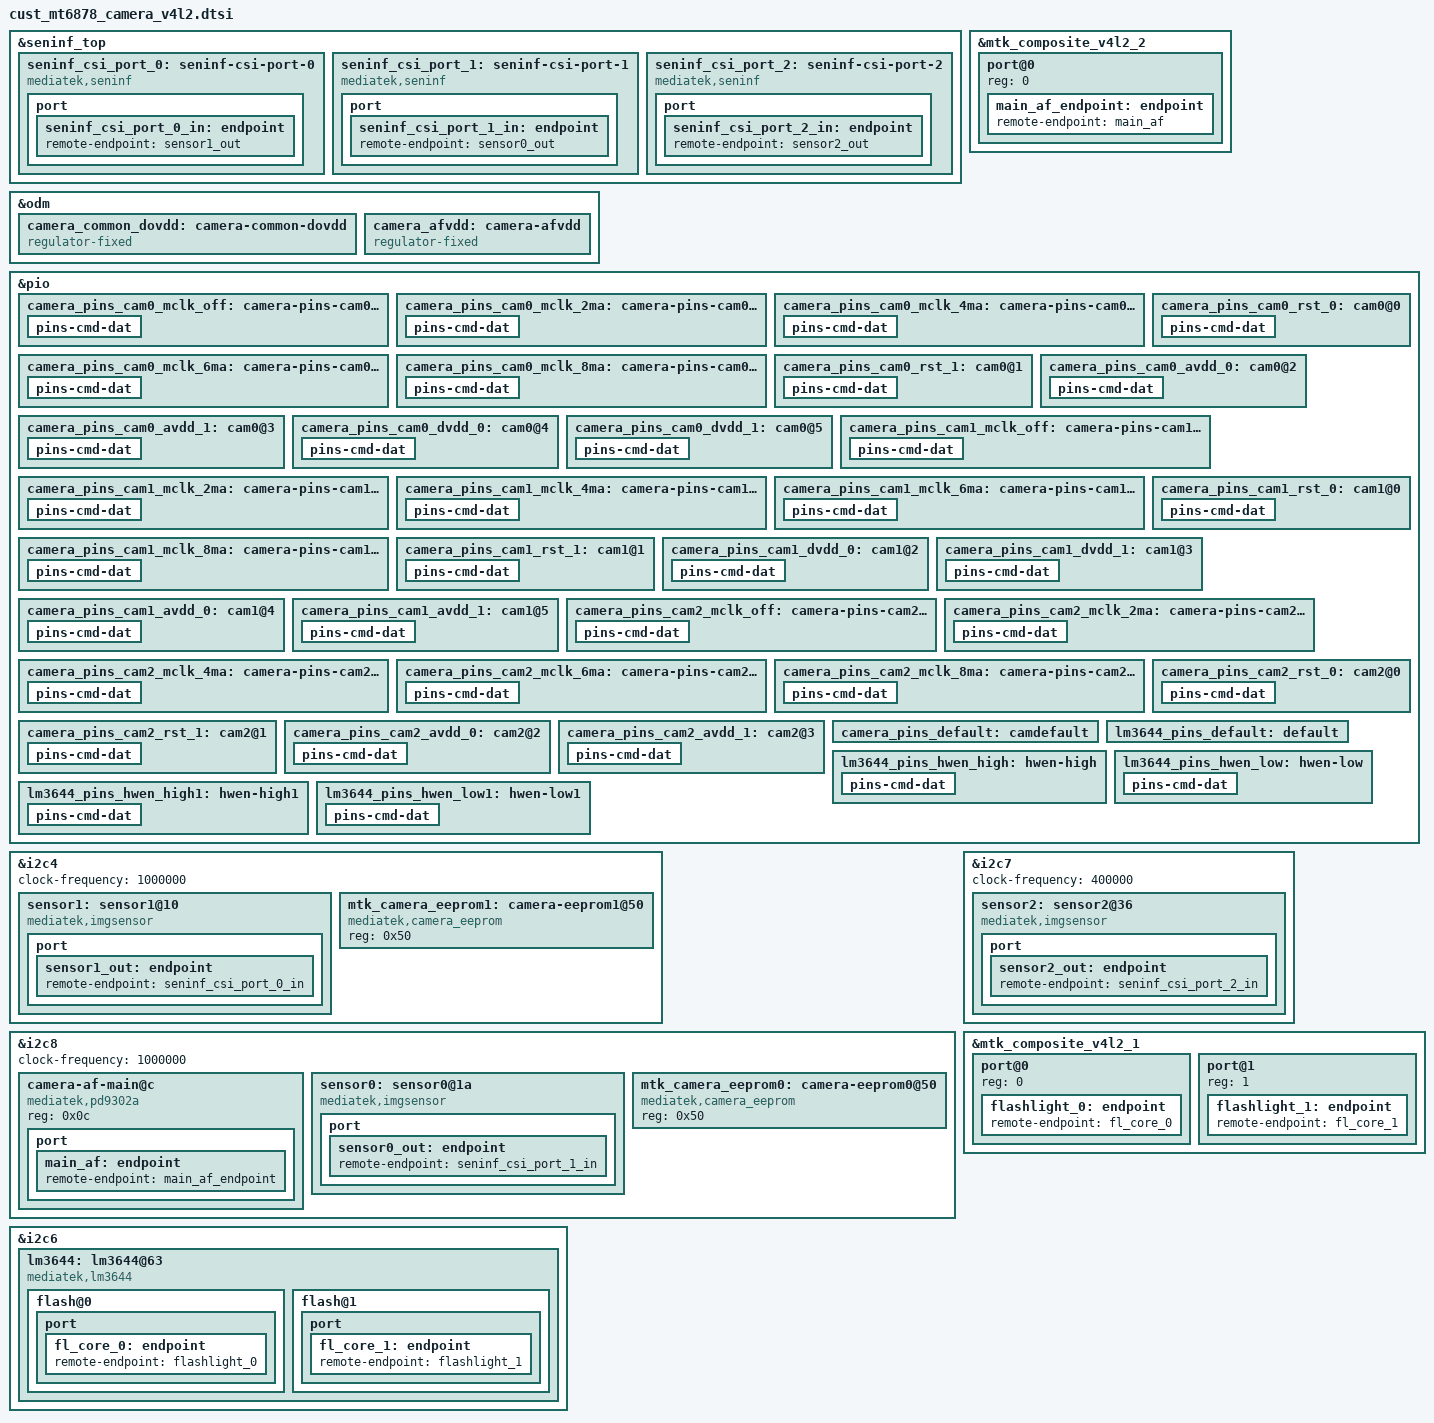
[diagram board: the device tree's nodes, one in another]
// SPDX-License-Identifier: GPL-2.0
/* Copyright (c) 2020 MediaTek Inc. */
#include <dt-bindings/clock/mt6878-clk.h>

&seninf_top {
		seninf_csi_port_0: seninf-csi-port-0 {
			compatible = "mediatek,seninf";
			csi-port = "0";
			dphy-settle-delay-dt = <17>;
			nvmem-cells = <&csi_efuse0>;
			nvmem-cell-names = "rg_csi";
			port {
				seninf_csi_port_0_in: endpoint {
					remote-endpoint = <&sensor1_out>;
				};
			};
		};

		seninf_csi_port_1: seninf-csi-port-1 {
			compatible = "mediatek,seninf";
			csi-port = "1";
			hs-trail-parameter = <0x20>;
			nvmem-cells = <&csi_efuse1>;
			nvmem-cell-names = "rg_csi";
			port {
				seninf_csi_port_1_in: endpoint {
					remote-endpoint = <&sensor0_out>;
				};
			};
		};

		seninf_csi_port_2: seninf-csi-port-2 {
			compatible = "mediatek,seninf";
			csi-port = "2A";
			hs-trail-parameter = <0x20>;
			nvmem-cells = <&csi_efuse2>;
			nvmem-cell-names = "rg_csi";
			port {
				seninf_csi_port_2_in: endpoint {
					remote-endpoint = <&sensor2_out>;
				};
			};
		};
};


/* CAMERA GPIO fixed to regulator */
&odm {
	camera_common_dovdd: camera-common-dovdd {
		compatible = "regulator-fixed";
		regulator-name = "camera-common-dovdd";
		regulator-min-microvolt = <1800000>;
		regulator-max-microvolt = <1800000>;
		enable-active-high;
		gpio = <&pio 23 0x0>;
	};
	camera_afvdd: camera-afvdd {
		compatible = "regulator-fixed";
		regulator-name = "camera-afvdd";
		regulator-min-microvolt = <2800000>;
		regulator-max-microvolt = <2800000>;
		enable-active-high;
		gpio = <&pio 1 0x0>;
	};
};

&mtk_composite_v4l2_2 {
	#address-cells = <1>;
	#size-cells = <0>;
	port@0 {
		reg = <0>;
		main_af_endpoint: endpoint {
			remote-endpoint = <&main_af>;
		};
	};
};

/* CAMERA GPIO standardization */
&pio {
	camera_pins_cam0_mclk_off: camera-pins-cam0-mclk-off {
		pins-cmd-dat {
			pinmux = <PINMUX_GPIO93__FUNC_GPIO93>;
			drive-strength = <1>;
		};
	};
	camera_pins_cam0_mclk_2ma: camera-pins-cam0-mclk-2ma {
		pins-cmd-dat {
			pinmux = <PINMUX_GPIO93__FUNC_CMMCLK1>;
			drive-strength = <0>;
		};
	};
	camera_pins_cam0_mclk_4ma: camera-pins-cam0-mclk-4ma {
		pins-cmd-dat {
			pinmux = <PINMUX_GPIO93__FUNC_CMMCLK1>;
			drive-strength = <1>;
		};
	};
	camera_pins_cam0_mclk_6ma: camera-pins-cam0-mclk-6ma {
		pins-cmd-dat {
			pinmux = <PINMUX_GPIO93__FUNC_CMMCLK1>;
			drive-strength = <2>;
		};
	};
	camera_pins_cam0_mclk_8ma: camera-pins-cam0-mclk-8ma {
		pins-cmd-dat {
			pinmux = <PINMUX_GPIO93__FUNC_CMMCLK1>;
			drive-strength = <3>;
		};
	};
	camera_pins_cam0_rst_0: cam0@0 {
		pins-cmd-dat {
			pinmux = <PINMUX_GPIO25__FUNC_GPIO25>;
			slew-rate = <1>;
			output-low;
		};
	};
	camera_pins_cam0_rst_1: cam0@1 {
		pins-cmd-dat {
			pinmux = <PINMUX_GPIO25__FUNC_GPIO25>;
			slew-rate = <1>;
			output-high;
		};
	};
	camera_pins_cam0_avdd_0: cam0@2 {
		pins-cmd-dat {
			pinmux = <PINMUX_GPIO22__FUNC_GPIO22>;
			slew-rate = <1>;
			output-low;
		};
	};
	camera_pins_cam0_avdd_1: cam0@3 {
		pins-cmd-dat {
			pinmux = <PINMUX_GPIO22__FUNC_GPIO22>;
			slew-rate = <1>;
			output-high;
		};
	};
	camera_pins_cam0_dvdd_0: cam0@4 {
		pins-cmd-dat {
			pinmux = <PINMUX_GPIO21__FUNC_GPIO21>;
			slew-rate = <1>;
			output-low;
		};
	};
	camera_pins_cam0_dvdd_1: cam0@5 {
		pins-cmd-dat {
			pinmux = <PINMUX_GPIO21__FUNC_GPIO21>;
			slew-rate = <1>;
			output-high;
		};
	};

	camera_pins_cam1_mclk_off: camera-pins-cam1-mclk-off {
		pins-cmd-dat {
			pinmux = <PINMUX_GPIO96__FUNC_GPIO96>;
			drive-strength = <1>;
		};
	};
	camera_pins_cam1_mclk_2ma: camera-pins-cam1-mclk-2ma {
		pins-cmd-dat {
			pinmux = <PINMUX_GPIO96__FUNC_CMMCLK4>;
			drive-strength = <0>;
		};
	};
	camera_pins_cam1_mclk_4ma: camera-pins-cam1-mclk-4ma {
		pins-cmd-dat {
			pinmux = <PINMUX_GPIO96__FUNC_CMMCLK4>;
			drive-strength = <1>;
		};
	};
	camera_pins_cam1_mclk_6ma: camera-pins-cam1-mclk-6ma {
		pins-cmd-dat {
			pinmux = <PINMUX_GPIO96__FUNC_CMMCLK4>;
			drive-strength = <2>;
		};
	};
	camera_pins_cam1_mclk_8ma: camera-pins-cam1-mclk-8ma {
		pins-cmd-dat {
			pinmux = <PINMUX_GPIO96__FUNC_CMMCLK4>;
			drive-strength = <3>;
		};
	};
	camera_pins_cam1_rst_0: cam1@0 {
		pins-cmd-dat {
			pinmux = <PINMUX_GPIO24__FUNC_GPIO24>;
			slew-rate = <1>;
			output-low;
		};
	};
	camera_pins_cam1_rst_1: cam1@1 {
		pins-cmd-dat {
			pinmux = <PINMUX_GPIO24__FUNC_GPIO24>;
			slew-rate = <1>;
			output-high;
		};
	};
	camera_pins_cam1_dvdd_0: cam1@2 {
		pins-cmd-dat {
			pinmux = <PINMUX_GPIO20__FUNC_GPIO20>;
			slew-rate = <1>;
			output-low;
		};
	};
	camera_pins_cam1_dvdd_1: cam1@3 {
		pins-cmd-dat {
			pinmux = <PINMUX_GPIO20__FUNC_GPIO20>;
			slew-rate = <1>;
			output-high;
		};
	};
	camera_pins_cam1_avdd_0: cam1@4 {
		pins-cmd-dat {
			pinmux = <PINMUX_GPIO19__FUNC_GPIO19>;
			slew-rate = <1>;
			output-low;
		};
	};
	camera_pins_cam1_avdd_1: cam1@5 {
		pins-cmd-dat {
			pinmux = <PINMUX_GPIO19__FUNC_GPIO19>;
			slew-rate = <1>;
			output-high;
		};
	};

	camera_pins_cam2_mclk_off: camera-pins-cam2-mclk-off {
		pins-cmd-dat {
			pinmux = <PINMUX_GPIO94__FUNC_GPIO94>;
			drive-strength = <1>;
		};
	};
	camera_pins_cam2_mclk_2ma: camera-pins-cam2-mclk-2ma {
		pins-cmd-dat {
			pinmux = <PINMUX_GPIO94__FUNC_CMMCLK2>;
			drive-strength = <0>;
		};
	};
	camera_pins_cam2_mclk_4ma: camera-pins-cam2-mclk-4ma {
		pins-cmd-dat {
			pinmux = <PINMUX_GPIO94__FUNC_CMMCLK2>;
			drive-strength = <1>;
		};
	};
	camera_pins_cam2_mclk_6ma: camera-pins-cam2-mclk-6ma {
		pins-cmd-dat {
			pinmux = <PINMUX_GPIO94__FUNC_CMMCLK2>;
			drive-strength = <2>;
		};
	};
	camera_pins_cam2_mclk_8ma: camera-pins-cam2-mclk-8ma {
		pins-cmd-dat {
			pinmux = <PINMUX_GPIO94__FUNC_CMMCLK2>;
			drive-strength = <3>;
		};
	};
	camera_pins_cam2_rst_0: cam2@0 {
		pins-cmd-dat {
			pinmux = <PINMUX_GPIO26__FUNC_GPIO26>;
			slew-rate = <1>;
			output-low;
		};
	};
	camera_pins_cam2_rst_1: cam2@1 {
		pins-cmd-dat {
			pinmux = <PINMUX_GPIO26__FUNC_GPIO26>;
			slew-rate = <1>;
			output-high;
		};
	};
	camera_pins_cam2_avdd_0: cam2@2 {
		pins-cmd-dat {
			pinmux = <PINMUX_GPIO28__FUNC_GPIO28>;
			slew-rate = <1>;
			output-low;
		};
	};
	camera_pins_cam2_avdd_1: cam2@3 {
		pins-cmd-dat {
			pinmux = <PINMUX_GPIO28__FUNC_GPIO28>;
			slew-rate = <1>;
			output-high;
		};
	};
	camera_pins_default: camdefault {
	};
};
/* CAMERA GPIO end */


&i2c4 {
	status = "okay";
	clock-frequency = <1000000>;

	sensor1: sensor1@10 {
		compatible = "mediatek,imgsensor";
		sensor-names = "gc16b3c_mipi_raw","gc16b3ctxd_mipi_raw";
		reg = <0x10>;

		#thermal-sensor-cells = <0>;

		pinctrl-names = "mclk_off",
				"mclk_2mA",
				"mclk_4mA",
				"mclk_6mA",
				"mclk_8mA",
				"rst_low",
				"rst_high",
				"dvdd_off",
				"dvdd_on",
				"avdd_off",
				"avdd_on";
		pinctrl-0 = <&camera_pins_cam1_mclk_off>;
		pinctrl-1 = <&camera_pins_cam1_mclk_2ma>;
		pinctrl-2 = <&camera_pins_cam1_mclk_4ma>;
		pinctrl-3 = <&camera_pins_cam1_mclk_6ma>;
		pinctrl-4 = <&camera_pins_cam1_mclk_8ma>;
		pinctrl-5 = <&camera_pins_cam1_rst_0>;
		pinctrl-6 = <&camera_pins_cam1_rst_1>;
		pinctrl-7 = <&camera_pins_cam1_dvdd_0>;
		pinctrl-8 = <&camera_pins_cam1_dvdd_1>;
		pinctrl-9 = <&camera_pins_cam1_avdd_0>;
		pinctrl-10 = <&camera_pins_cam1_avdd_1>;

		dovdd-supply = <&camera_common_dovdd>;
		clocks = <&topckgen_clk CLK_TOP_UVPLL192M_D32>,
			<&topckgen_clk CLK_TOP_UVPLL192M_D16>,
			<&topckgen_clk CLK_TOP_OSC_D20>,
			<&topckgen_clk CLK_TOP_UVPLL192M_D10>,
			<&topckgen_clk CLK_TOP_UVPLL192M_D8>,
			<&topckgen_clk CLK_TOP_TCK_26M_MX9>,
			<&topckgen_clk CLK_TOP_UNIVPLL_D6_D8>,
			<&topckgen_clk CLK_TOP_CAMTG5_SEL>;
		clock-names = "6", "12", "13", "19.2", "24", "26", "52", "mclk";

		status = "okay";
		port {
			sensor1_out: endpoint {
				remote-endpoint = <&seninf_csi_port_0_in>;
			};
		};
	};
	mtk_camera_eeprom1:camera-eeprom1@50 {
		compatible = "mediatek,camera_eeprom";
		reg = <0x50>;
		status = "okay";
	};
};


&i2c8 {
	status = "okay";
	clock-frequency = <1000000>;

	camera-af-main@c {
		compatible = "mediatek,pd9302a";
		reg = <0x0c>;
		port {
			main_af: endpoint {
				remote-endpoint = <&main_af_endpoint>;
			};
		};
	};

	sensor0: sensor0@1a {
		compatible = "mediatek,imgsensor";
		sensor-names = "imx882_mipi_raw", "imx882txd_mipi_raw";
		reg = <0x1a>;

		#thermal-sensor-cells = <0>;

		pinctrl-names = "mclk_off",
				"mclk_2mA",
				"mclk_4mA",
				"mclk_6mA",
				"mclk_8mA",
				"rst_low",
				"rst_high",
				"avdd_off",
				"avdd_on",
				"dvdd_off",
				"dvdd_on";

		pinctrl-0 = <&camera_pins_cam0_mclk_off>;
		pinctrl-1 = <&camera_pins_cam0_mclk_2ma>;
		pinctrl-2 = <&camera_pins_cam0_mclk_4ma>;
		pinctrl-3 = <&camera_pins_cam0_mclk_6ma>;
		pinctrl-4 = <&camera_pins_cam0_mclk_8ma>;
		pinctrl-5 = <&camera_pins_cam0_rst_0>;
		pinctrl-6 = <&camera_pins_cam0_rst_1>;
		pinctrl-7 = <&camera_pins_cam0_avdd_0>;
		pinctrl-8 = <&camera_pins_cam0_avdd_1>;
		pinctrl-9 = <&camera_pins_cam0_dvdd_0>;
		pinctrl-10 = <&camera_pins_cam0_dvdd_1>;
		afvdd-supply = <&camera_afvdd>;
		dovdd-supply = <&camera_common_dovdd>;
		clocks = <&topckgen_clk CLK_TOP_UVPLL192M_D32>,
			<&topckgen_clk CLK_TOP_UVPLL192M_D16>,
			<&topckgen_clk CLK_TOP_OSC_D20>,
			<&topckgen_clk CLK_TOP_UVPLL192M_D10>,
			<&topckgen_clk CLK_TOP_UVPLL192M_D8>,
			<&topckgen_clk CLK_TOP_TCK_26M_MX9>,
			<&topckgen_clk CLK_TOP_UNIVPLL_D6_D8>,
			<&topckgen_clk CLK_TOP_CAMTG2_SEL>;
		clock-names = "6", "12", "13", "19.2", "24", "26", "52", "mclk";


		status = "okay";
		port {
			sensor0_out: endpoint {
				remote-endpoint = <&seninf_csi_port_1_in>;
			};
		};
	};
	mtk_camera_eeprom0:camera-eeprom0@50 {
		compatible = "mediatek,camera_eeprom";
		reg = <0x50>;
		status = "okay";
	};
};

&i2c7 {
	status = "okay";
	clock-frequency = <400000>;

	sensor2: sensor2@36 {
		compatible = "mediatek,imgsensor";
		sensor-names = "sc202cs_mipi_raw","sc202cssj_mipi_raw";
		reg = <0x36>;
		#reindex-to = <0>;

		cust-aov-csi-clk = <312>;

		#thermal-sensor-cells = <0>;

		pinctrl-names = "mclk_off",
				"mclk_2mA",
				"mclk_4mA",
				"mclk_6mA",
				"mclk_8mA",
				"rst_low",
				"rst_high",
				"avdd_off",
				"avdd_on";
		pinctrl-0 = <&camera_pins_cam2_mclk_off>;
		pinctrl-1 = <&camera_pins_cam2_mclk_2ma>;
		pinctrl-2 = <&camera_pins_cam2_mclk_4ma>;
		pinctrl-3 = <&camera_pins_cam2_mclk_6ma>;
		pinctrl-4 = <&camera_pins_cam2_mclk_8ma>;
		pinctrl-5 = <&camera_pins_cam2_rst_0>;
		pinctrl-6 = <&camera_pins_cam2_rst_1>;
		pinctrl-7 = <&camera_pins_cam2_avdd_0>;
		pinctrl-8 = <&camera_pins_cam2_avdd_1>;


		dovdd-supply = <&camera_common_dovdd>;
		clocks = <&topckgen_clk CLK_TOP_UVPLL192M_D32>,
			<&topckgen_clk CLK_TOP_UVPLL192M_D16>,
			<&topckgen_clk CLK_TOP_OSC_D20>,
			<&topckgen_clk CLK_TOP_UVPLL192M_D10>,
			<&topckgen_clk CLK_TOP_UVPLL192M_D8>,
			<&topckgen_clk CLK_TOP_TCK_26M_MX9>,
			<&topckgen_clk CLK_TOP_UNIVPLL_D6_D8>,
			<&topckgen_clk CLK_TOP_CAMTG3_SEL>;
		clock-names = "6", "12", "13", "19.2", "24", "26", "52", "mclk";


		status = "okay";
		port {
			sensor2_out: endpoint {
				remote-endpoint = <&seninf_csi_port_2_in>;
			};
		};
	};
};



&i2c6 {
	#address-cells = <1>;
	#size-cells = <0>;
	lm3644:lm3644@63 {
		compatible = "mediatek,lm3644";
		#address-cells = <1>;
		#size-cells = <0>;
		reg = <0x63>;
		#cooling-cells = <2>;
		pinctrl-names = "default", "hwen-high", "hwen-low", "hwen-high1", "hwen-low1";
		pinctrl-0 = <&lm3644_pins_default>;
		pinctrl-1 = <&lm3644_pins_hwen_high>;
		pinctrl-2 = <&lm3644_pins_hwen_low>;
		pinctrl-3 = <&lm3644_pins_hwen_high1>;
		pinctrl-4 = <&lm3644_pins_hwen_low1>;
		status = "okay";
		flash@0{
			reg = <0>;
			type = <0>;
			ct = <0>;
			part = <0>;
			port {
				fl_core_0: endpoint {
					remote-endpoint = <&flashlight_0>;
				};
			};
		};
		flash@1{
			reg = <1>;
			type = <0>;
			ct = <1>;
			part = <0>;
			port {
				fl_core_1: endpoint {
					remote-endpoint = <&flashlight_1>;
				};
			};
		};
	};
};
&pio {
	lm3644_pins_default: default {
	};

	lm3644_pins_hwen_high: hwen-high {
		pins-cmd-dat {
			pinmux = <PINMUX_GPIO155__FUNC_GPIO155>;
			slew-rate = <1>;
			output-high;
		};
	};

	lm3644_pins_hwen_low: hwen-low {
		pins-cmd-dat {
			pinmux = <PINMUX_GPIO155__FUNC_GPIO155>;
			slew-rate = <1>;
			output-low;
		};
	};

	lm3644_pins_hwen_high1: hwen-high1 {
		pins-cmd-dat {
			pinmux = <PINMUX_GPIO151__FUNC_GPIO151>;
			slew-rate = <1>;
			output-high;
		};
	};

	lm3644_pins_hwen_low1: hwen-low1 {
		pins-cmd-dat {
			pinmux = <PINMUX_GPIO151__FUNC_GPIO151>;
			slew-rate = <1>;
			output-low;
		};
	};
};

&mtk_composite_v4l2_1 {
	#address-cells = <1>;
	#size-cells = <0>;
	port@0 {
		reg = <0>;
		flashlight_0: endpoint {
			remote-endpoint = <&fl_core_0>;
		};
	};
	port@1 {
		reg = <1>;
		flashlight_1: endpoint {
			remote-endpoint = <&fl_core_1>;
		};
	};
};
